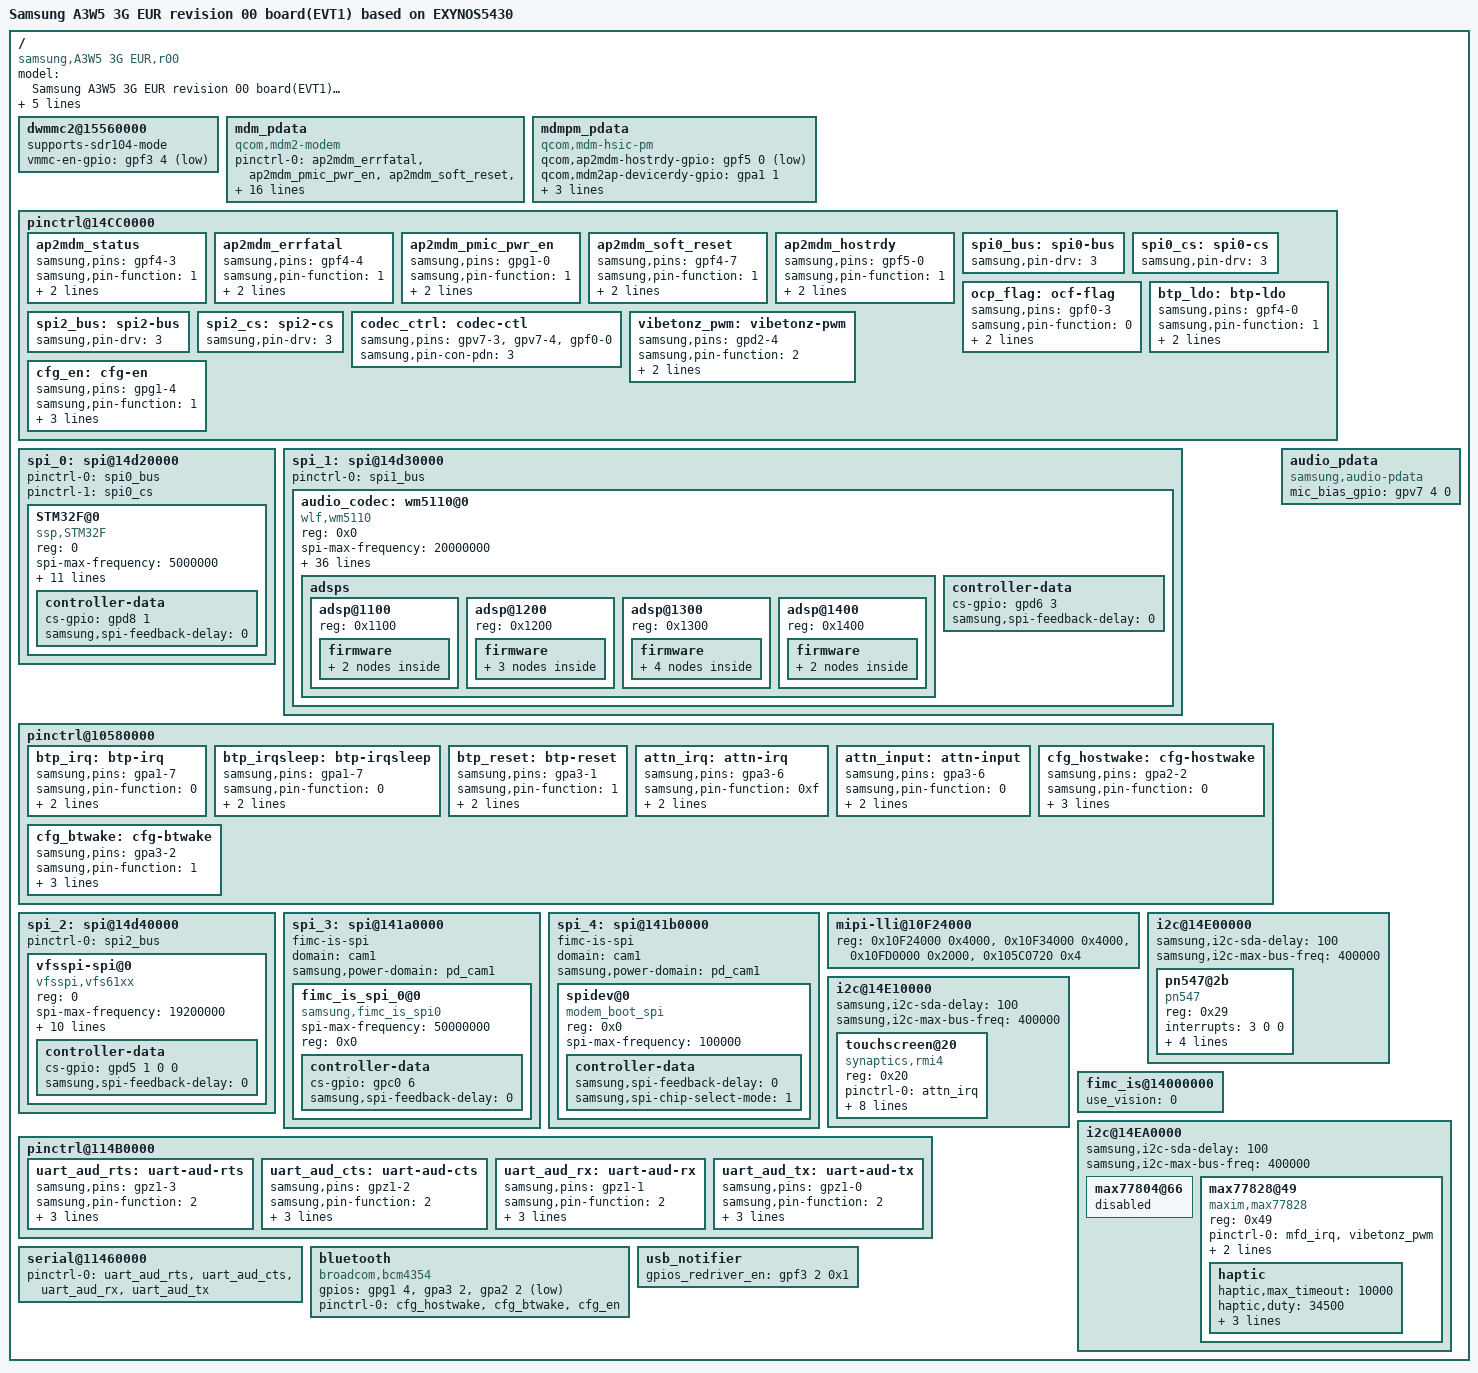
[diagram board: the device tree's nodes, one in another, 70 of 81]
/*
 * SAMSUNG UNIVERSAL5430 board device tree source
 *
 * Copyright (c) 2013 Samsung Electronics Co., Ltd.
 *		http://www.samsung.com
 *
 * This program is free software; you can redistribute it and/or modify
 * it under the terms of the GNU General Public License version 2 as
 * published by the Free Software Foundation.
*/

/dts-v1/;
#include "exynos5430-a3w5_common.dtsi"


/ {
	model = "Samsung A3W5 3G EUR revision 00 board(EVT1) based on EXYNOS5430";
	model_info-chip = <5430>;
	model_info-platform = "a3w53g";
	model_info-subtype = "a3w53g_eur_open";
	model_info-hw_rev = <0>;
	model_info-hw_rev_end = <255>; /* If add new dts file for new hw , it is set to <x>. x is suppored max system revision by this dts */
	compatible = "samsung,A3W5 3G EUR,r00", "samsung,exynos5430";

	dwmmc2@15560000 {
		supports-sdr104-mode;
		vmmc-en-gpio = <&gpf3 4 0x1>;
	};

	/* mdm_interface_driver: LTE */
	mdm_pdata {
		compatible = "qcom,mdm2-modem";
		pinctrl-names = "default";
		pinctrl-0 = <&ap2mdm_errfatal &ap2mdm_pmic_pwr_en &ap2mdm_soft_reset &ap2mdm_hostrdy &ap2mdm_status>;

		qcom,ramdump-delay-ms = <2000>;
		qcom,ramdump-timeout-ms = <120000>;
		qcom,vddmin-modes  = "normal";
		qcom,vddmin-drive-strength = <8>;
		qcom,sysmon-subsys-id = <19>;
		//qcom,early-power-on;
		//status = "disabled";

		qcom,mdm2ap-errfatal-gpio = <&gpa2 6 0x0>;
		qcom,ap2mdm-errfatal-gpio = <&gpf4 4 0x1>;
		qcom,mdm2ap-status-gpio   = <&gpa2 3 0xf>;
		qcom,ap2mdm-status-gpio   = <&gpf4 3 0x1>;
		qcom,ap2mdm-soft-reset-gpio = <&gpf4 7 0x1>;
		qcom,ap2mdm-pmic-pwr-en-gpio = <&gpg1 0 0x1>;
		qcom,mdm2ap-pblrdy-gpio = <&gpa1 0  0x0>;
		qcom,ap2mdm-wakeup-gpio = <&gpg2 4  0x1>;

		qcom,ap2mdm-vddmin-gpio = <&gpf4 5 0x1>;
		qcom,mdm2ap-vddmin-gpio = <&gpa2 5 0x0>;
		//qcom,ap2mdm-chnlrdy-gpio = <&msmgpio 106 0x00>;
		status = "ok";

	};
	/* mdm_interface_driver: LTE */
	mdmpm_pdata {
		compatible = "qcom,mdm-hsic-pm";
		qcom,ap2mdm-hostrdy-gpio = <&gpf5 0 0x1>;
		qcom,mdm2ap-devicerdy-gpio = <&gpa1 1 0x0>;
		qcom,mdm2ap-hostwake-gpio = <&gpa1 2 0xf>;

		reg = <0x15510000 0x100>, /* EHCI */
		      <0x15530000 0x100>, /* PHY */
		      <0x105C0704 0xC>, /* PMU */
		      <0x156E0204 0xC>; /* USB phy clk */
	};

	pinctrl@14CC0000 {
		ap2mdm_status: ap2mdm_status{
			samsung,pins = "gpf4-3";
			samsung,pin-function = <1>;
			samsung,pin-con-pdn = <3>;
			samsung,pin-pud-pdn = <0>;
		};
		ap2mdm_errfatal: ap2mdm_errfatal {
			samsung,pins = "gpf4-4";
			samsung,pin-function = <1>;
			samsung,pin-con-pdn = <3>;
			samsung,pin-pud-pdn = <0>;
		};
		ap2mdm_pmic_pwr_en: ap2mdm_pmic_pwr_en {
			samsung,pins = "gpg1-0";
			samsung,pin-function = <1>;
			samsung,pin-con-pdn = <3>;
			samsung,pin-pud-pdn = <0>;
		};
		ap2mdm_soft_reset: ap2mdm_soft_reset {
			samsung,pins = "gpf4-7";
			samsung,pin-function = <1>;
			samsung,pin-con-pdn = <3>;
			samsung,pin-pud-pdn = <0>;
		};
		ap2mdm_hostrdy: ap2mdm_hostrdy {
			samsung,pins = "gpf5-0";
			samsung,pin-function = <1>;
			samsung,pin-con-pdn = <3>;
			samsung,pin-pud-pdn = <0>;
		};
	};


	pinctrl@14CC0000 {
		spi0_bus: spi0-bus {
			samsung,pin-drv = <3>;
		};
		spi0_cs: spi0-cs {
			samsung,pin-drv = <3>;
		};
	};

	spi_0: spi@14d20000 {
		#address-cells = <1>;
		#size-cells = <0>;
		pinctrl-names = "default";
		pinctrl-0 = <&spi0_bus>;
		pinctrl-1 = <&spi0_cs>;

		STM32F@0 {
			compatible = "ssp,STM32F";
			reg = <0>;
			spi-max-frequency = <5000000>;
			pinctrl-names = "default";
			pinctrl-0 = <&ssp_irq &ssp_irq2 &ssp_ap_int &ssp_reset>;

			gpio-controller;
			#gpio-cells = <2>;
			ssp-irq = <&gpa3 3 0x01>;
			ssp-irq2 = <&gpa3 4 0x00>;
			ssp-ap-int = <&gpa3 7 0x00>;
			ssp-reset = <&gpd4 0 0x00>;
			ssp-acc-position = <6>;
			ssp-mag-position = <3>;
			ssp-sns-combination = <0>;
			ssp-ap-rev = <1>;

			controller-data {
				cs-gpio = <&gpd8 1 0>;
				samsung,spi-feedback-delay = <0>;
				};
			};
	};

	spi_1: spi@14d30000 {
		#address-cells = <1>;
		#size-cells = <0>;
		pinctrl-names = "default";
		pinctrl-0 = <&spi1_bus>;

		audio_codec: wm5110@0 {
			compatible = "wlf,wm5110";
			reg = <0x0>;
			spi-max-frequency = <20000000>;
			interrupts = <4 0 0>;
			interrupt-parent = <&gpa0>;

			gpio-controller;
			#gpio-cells = <2>;

			pinctrl-names ="default";
			pinctrl-0 = <&codec_ctrl>;

			wlf,reset = <&gpv7 3 0>;
			wlf,ldoena = <&gpf0 0 0>;
			wlf,init-mic-delay = <30>;
			wlf,micd-detect-debounce = <300>;
			wlf,micd-bias-start-time = <0x1>;
			wlf,micd-rate = <0x7>;
			wlf,micd-dbtime = <0x1>;
			wlf,micd-timeout = <1000>;
			wlf,micd-force-micbias;
			wlf,micd-ranges = <
				139 226
				295 115
				752 114
				1257 217
			>;

			wlf,micd-configs = <
				0x0 1 0
			>;

			wlf,micbias1 = <2800 0 1 0 0>;
			wlf,micbias2 = <1800 0 1 0 0>;
			wlf,micbias3 = <1800 0 1 0 0>;

			wlf,gpio-defaults = <
				0xA101
				0xA101
				0xA101
				0xA101
				0x8101
			>;

			wlf,gpsw = <0x3>;
			wlf,use-jd-gpio;
			wlf,jd-gpio-nopull;
			wlf,micd-software-compare;

			wlf,max-channels-clocked = <2 0 0>;
			/* 0:MICVDD 1:MICBIAS1 2:MICBIAS2 3:MICBIAS3 */
			wlf,dmic-ref = <0 1 3 0>;
			/* 1st cell:IN1 2rd cell:IN2 3nd cell:IN3 4th cell:IN4 */
			wlf,inmode = <2 0 2 0>;

			AVDD-supply = <&ldo3_reg>;
			LDOVDD-supply = <&ldo3_reg>;
			DBVDD1-supply = <&ldo3_reg>;

			CPVDD-supply = <&ldo3_reg>;
			DBVDD2-supply = <&ldo3_reg>;
			DBVDD3-supply = <&ldo3_reg>;
			SPKVDDL-supply = <&ldo3_reg>;
			SPKVDDR-supply = <&ldo3_reg>;

			adsps {
				#address-cells = <1>;
				#size-cells = <0>;

				adsp@1100 {
					reg = <0x1100>;
					firmware {
						EDAC {
							wlf,wmfw-file = "edac";
							wlf,bin-file = "edac";
						};
						TRACE {
							wlf,wmfw-file = "trace";
							wlf,compr-caps = <1 8 0x4 1 8000 16000 24000>;
						};
					};
				};
				adsp@1200 {
					reg = <0x1200>;
					firmware {
						TX_NB {
							wlf,wmfw-file = "tx-nb";
						};
						TX_WB {
							wlf,wmfw-file = "tx-wb";
						};
						TX_SWB {
							wlf,wmfw-file = "tx-swb";
						};
					};
				};
				adsp@1300 {
					reg = <0x1300>;
					firmware {
						TX_NB {
							wlf,wmfw-file = "tx-nb";
							wlf,bin-file = "tx-nb";
						};
						TX_WB {
							wlf,wmfw-file = "tx-wb";
							wlf,bin-file = "tx-wb";
						};
						TX_SWB {
							wlf,wmfw-file = "tx-swb";
							wlf,bin-file = "tx-swb";
						};
						VOICECONTROL {
							wlf,wmfw-file = "ez2-control";
							wlf,bin-file = "ez2-control";
						};
					};
				};
				adsp@1400 {
					reg = <0x1400>;
					firmware {
						RX_NB {
							wlf,wmfw-file = "rx-anc-nb";
							wlf,bin-file = "rx-anc-nb";
						};
						RX_WB {
							wlf,wmfw-file = "rx-anc-wb";
							wlf,bin-file = "rx-anc-wb";
						};
					};
				};
			};
			controller-data {
				cs-gpio = <&gpd6 3 0>;
				samsung,spi-feedback-delay = <0>;
			};
		};
	};

	pinctrl@10580000 {
		btp_irq: btp-irq {
			samsung,pins = "gpa1-7";
			samsung,pin-function = <0>;
			samsung,pin-pud = <3>;
			samsung,pin-drv = <3>;
		};
		btp_irqsleep: btp-irqsleep {
			samsung,pins = "gpa1-7";
			samsung,pin-function = <0>;
			samsung,pin-pud = <1>;
			samsung,pin-drv = <0>;
		};
		btp_reset: btp-reset {
			samsung,pins = "gpa3-1";
			samsung,pin-function = <1>;
			samsung,pin-pud = <1>;
			samsung,pin-drv = <0>;
		};
	};
	pinctrl@14CC0000 {
		ocp_flag: ocf-flag {
			samsung,pins = "gpf0-3";
			samsung,pin-function = <0>;
			samsung,pin-pud = <3>;
			samsung,pin-drv = <3>;
		};
		btp_ldo: btp-ldo {
			samsung,pins = "gpf4-0";
			samsung,pin-function = <1>;
			samsung,pin-pud = <1>;
			samsung,pin-drv = <0>;
		};
		spi2_bus: spi2-bus {
			samsung,pin-drv = <3>;
		};

		spi2_cs: spi2-cs {
			samsung,pin-drv = <3>;
		};
	};
	spi_2: spi@14d40000 {
		/delete-property/ dma-mode;
		/delete-property/ dmas;
		/delete-property/ dma-names;
		#address-cells = <1>;
		#size-cells = <0>;
		pinctrl-names = "default";
		pinctrl-0 = <&spi2_bus>;

		vfsspi-spi@0 {
			compatible = "vfsspi,vfs61xx";
			reg = <0>;
			spi-max-frequency = <19200000>;
			pinctrl-names = "default", "sleep";
			pinctrl-0 = <&btp_irq &btp_reset &btp_ldo &ocp_flag>;
			pinctrl-1 = <&btp_irqsleep &btp_reset &btp_ldo &ocp_flag>;

			gpio-controller;
			#gpio-cells = <2>;

			vfsspi-sleepPin = <&gpa3 1 0x00>;
			vfsspi-drdyPin = <&gpa1 7 0x00>;
			vfsspi-ldoPin = <&gpf4  0 0x00>;
			/* vfsspi-ocpflag = <&gpf0 3 0x00>; */
			vfsspi-orient = <1>;
			vfsspi-ldocontrol = <1>;

			controller-data {
				cs-gpio = <&gpd5 1 0 0 3>;
				samsung,spi-feedback-delay = <0>;
			};
		};
	};

	spi_3: spi@141a0000 {
		fimc-is-spi;
		domain = "cam1";
		samsung,power-domain = <&pd_cam1>;

		#address-cells = <1>;
		#size-cells = <0>;

		fimc_is_spi_0@0 {
			compatible = "samsung,fimc_is_spi0";
			spi-max-frequency = <50000000>;
			reg = <0x0>;

			controller-data {
				cs-gpio = <&gpc0 6 0>;
				samsung,spi-feedback-delay = <0>;
			};
		};
	};

	spi_4: spi@141b0000 {
		fimc-is-spi;
		domain = "cam1";
		samsung,power-domain = <&pd_cam1>;

		#address-cells = <1>;
		#size-cells = <0>;

		spidev@0 {
			#address-cells = <1>;
			#size-cells = <1>;
			compatible = "modem_boot_spi";
			reg = <0x0>;
			spi-max-frequency = <100000>;

			controller-data {
				samsung,spi-feedback-delay = <0>;
				samsung,spi-chip-select-mode = <1>;
			};
		};
	};


	mipi-lli@10F24000 {
		reg = <0x10F24000 0x4000>,
		      <0x10F34000 0x4000>,
		      <0x10FD0000 0x2000>,
		      <0x105C0720 0x4>;
	};

	audio_pdata {
		compatible = "samsung,audio-pdata";

		mic_bias_gpio = <&gpv7 4 0>;
		status = "okay";
	};

	pinctrl@14CC0000 {
		codec_ctrl: codec-ctl {
			samsung,pins ="gpv7-3", "gpv7-4", "gpf0-0";
			samsung,pin-con-pdn =<3>;
		};
	};

	i2c@14E00000 {
		samsung,i2c-sda-delay = <100>;
		samsung,i2c-max-bus-freq = <400000>;
		#address-cells = <1>;
		#size-cells = <0>;
		status = "okay";

		pn547@2b {
			compatible = "pn547";
			reg = <0x29>;

			interrupts = <3 0 0>;
			interrupt-parent = <&gpa1>;

			pn547-en = <&gpf1 4 0>;
			pn547-irq = <&gpa1 3 0>;
			pn547-firmware = <&gpj0 2 0>;
		};
	};

	pinctrl@10580000 {
		attn_irq: attn-irq {
			samsung,pins = "gpa3-6";
			samsung,pin-function = <0xf>;
			samsung,pin-pud = <0>;
			samsung,pin-drv = <0>;
		};
		attn_input: attn-input {
			samsung,pins = "gpa3-6";
			samsung,pin-function = <0>;
			samsung,pin-pud = <1>;
			samsung,pin-drv = <0>;
		};
	};

	i2c@14E10000 {
		samsung,i2c-sda-delay = <100>;
		samsung,i2c-max-bus-freq = <400000>;
		status = "okay";
		touchscreen@20 {
			compatible = "synaptics,rmi4";
			reg = <0x20>;
			pinctrl-names = "on_state", "off_state";
			pinctrl-0 = <&attn_irq>;
			pinctrl-1 = <&attn_input>;
			synaptics,irq_gpio = <&gpa3 6 0>;
			synaptics,irq_type = <8200>;
			synaptics,max_coords = <1439 2559>;	/* x y */
			synaptics,num_lines = <29 16>;		/* rx tx */
			synaptics,regulator_dvdd = "tsp_io";
			synaptics,regulator_avdd = "tsp_avdd";
			synaptics,project_name = "KQ";
		};
	};

	fimc_is@14000000 {
		use_vision = <0>;
	};

	pinctrl@14CC0000 {
		vibetonz_pwm: vibetonz-pwm {
		      samsung,pins = "gpd2-4";
		      samsung,pin-function = <2>;
		      samsung,pin-pud = <0>;
		      samsung,pin-drv = <0>;
	      };
	};
	i2c@14EA0000 {
		samsung,i2c-sda-delay = <100>;
		samsung,i2c-max-bus-freq = <400000>;
		status = "okay";
		max77804@66 {
			status = "disabled";
		};
		max77828@49 {
			compatible = "maxim,max77828";
			reg = <0x49>;
			pinctrl-names = "default";
			pinctrl-0 = <&mfd_irq &vibetonz_pwm>;
			max77828,irq-gpio = <&gpa1 4 1>;
			max77828,wakeup;
			haptic {
				haptic,max_timeout = <10000>;
				haptic,duty = <34500>;
				haptic,period = <38240>;
				haptic,pwm_id = <0>;
				haptic,regulator_name = "VCC_3.0V_MOTOR_AP";
			};
		};
	};

	pinctrl@114B0000 {
		uart_aud_rts: uart-aud-rts {
			samsung,pins = "gpz1-3";
			samsung,pin-function = <2>;
			samsung,pin-pud = <0>;
			samsung,pin-con-pdn = <1>;
			samsung,pin-pud-pdn = <0>;
		};

		uart_aud_cts: uart-aud-cts {
			samsung,pins = "gpz1-2";
			samsung,pin-function = <2>;
			samsung,pin-pud = <0>;
			samsung,pin-con-pdn = <2>;
			samsung,pin-pud-pdn = <0>;
		};

		uart_aud_rx: uart-aud-rx {
			samsung,pins = "gpz1-1";
			samsung,pin-function = <2>;
			samsung,pin-pud = <0>;
			samsung,pin-con-pdn = <2>;
			samsung,pin-pud-pdn = <0>;
		};

		uart_aud_tx: uart-aud-tx {
			samsung,pins = "gpz1-0";
			samsung,pin-function = <2>;
			samsung,pin-pud = <0>;
			samsung,pin-con-pdn = <1>;
			samsung,pin-pud-pdn = <0>;
		};
	};

	serial@11460000 {
		pinctrl-0 = <&uart_aud_rts &uart_aud_cts &uart_aud_rx &uart_aud_tx>;
	};

/*
			samsung,pins = "gpa0-0";

			samsung,pin-function = <2>;
			0 : input, 1 : output 2 : special_function

			samsung,pin-pud = <0>;
			0 : reserved 1 : pull down 2 : reserved 3 : pull up

			samsung,pin-con-pdn = <2>;
			0 : output0 1 : output1 2: input 3: previous state

			samsung,pin-pud-pdn = <0>;
			0 : pull up/down disable 1 : pull down 2 : reserved 3 : pull up
*/

	pinctrl@14CC0000 {
		cfg_en: cfg-en {
			samsung,pins ="gpg1-4";
			samsung,pin-function = <1>;
			samsung,pin-pud = <1>;
			samsung,pin-con-pdn = <3>;
			samsung,pin-pud-pdn = <1>;
		};
	};

	pinctrl@10580000{
		cfg_hostwake: cfg-hostwake {
			samsung,pins = "gpa2-2";
			samsung,pin-function = <0>;
			samsung,pin-pud = <2>;
			samsung,pin-con-pdn = <2>;
			samsung,pin-pud-pdn = <0>;
		};

		cfg_btwake: cfg-btwake {
			samsung,pins = "gpa3-2";
			samsung,pin-function = <1>;
			samsung,pin-pud = <1>;
			samsung,pin-con-pdn = <0>;
			samsung,pin-pud-pdn = <1>;
		};
	};

	bluetooth {
		compatible = "broadcom,bcm4354";

		gpios = <&gpg1 4 0	/*BT_EN*/
				&gpa3 2 0	/*BT_WAKE*/
				&gpa2 2 0xF	/*BT_HOST_WAKE*/ >;

		pinctrl-names = "default";
		pinctrl-0=<&cfg_hostwake &cfg_btwake &cfg_en>;
		status = "okay";
	};

	usb_notifier {
		gpios_redriver_en = <&gpf3 2 0x1>; /* USB3.0_REDRIVER_EN */
	};
};
